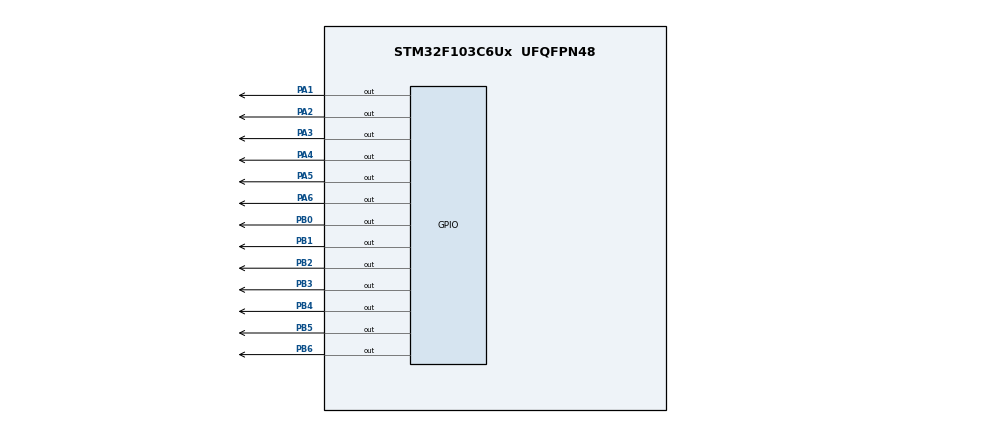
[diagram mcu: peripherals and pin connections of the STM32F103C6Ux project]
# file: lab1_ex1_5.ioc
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Mcu.Family=STM32F1
Mcu.Name=STM32F103C6Ux
Mcu.Package=UFQFPN48
NVIC.PriorityGroup=NVIC_PRIORITYGROUP_4
PA1.Signal=GPIO_Output
PA2.Signal=GPIO_Output
PA3.Signal=GPIO_Output
PA4.Signal=GPIO_Output
PA5.Signal=GPIO_Output
PA6.Signal=GPIO_Output
PB0.Signal=GPIO_Output
PB1.Signal=GPIO_Output
PB2.Signal=GPIO_Output
PB3.Signal=GPIO_Output
PB4.Signal=GPIO_Output
PB5.Signal=GPIO_Output
PB6.Signal=GPIO_Output
ProjectManager.HeapSize=0x200
ProjectManager.StackSize=0x400
ProjectManager.TargetToolchain=STM32CubeIDE
RCC.APB1Freq_Value=8000000
RCC.APB2Freq_Value=8000000
VP_SYS_VS_ND.Mode=No_Debug
board=custom

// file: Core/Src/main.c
/* USER CODE BEGIN Header */
/**
  ******************************************************************************
  * @file           : main.c
  * @brief          : Main program body
  ******************************************************************************
  * @attention
  *
  * <h2><center>&copy; Copyright (c) 2022 STMicroelectronics.
  * All rights reserved.</center></h2>
  *
  * This software component is licensed by ST under BSD 3-Clause license,
  * the "License"; You may not use this file except in compliance with the
  * License. You may obtain a copy of the License at:
  *                        opensource.org/licenses/BSD-3-Clause
  *
  ******************************************************************************
  */
/* USER CODE END Header */
#include "main.h"

void SystemClock_Config(void);
static void MX_GPIO_Init(void);

int main(void)
{

  /* MCU Configuration--------------------------------------------------------*/

  /* Reset of all peripherals, Initializes the Flash interface and the Systick. */
  HAL_Init();

  /* Configure the system clock */
  SystemClock_Config();

  /* Initialize all configured peripherals */
  MX_GPIO_Init();
  /* USER CODE BEGIN 2 */
  void display7SEG (int num){
  	char led7seg[10] = {0xC0, 0xF9, 0xA4, 0xB0, 0x99, 0x92, 0x82, 0xF8, 0x80, 0x90};
  	for (int i = 0; i < 7; i++){
  		HAL_GPIO_WritePin(GPIOB, GPIO_PIN_0 << i, (led7seg[num] >> i) & 1);
  	}
  }
  /* USER CODE END 2 */

  /* Infinite loop */
  /* USER CODE BEGIN WHILE */
  int counter = 9;
    while (1)
    {
  	  switch (counter){
  	  case 9: //1RED -2 GREEN
  		  HAL_GPIO_WritePin(GPIOA, GPIO_PIN_1, GPIO_PIN_RESET);
  		  HAL_GPIO_WritePin(GPIOA, GPIO_PIN_2, GPIO_PIN_SET);
  		  HAL_GPIO_WritePin(GPIOA, GPIO_PIN_3, GPIO_PIN_SET);
  		  HAL_GPIO_WritePin(GPIOA, GPIO_PIN_4, GPIO_PIN_SET);
  		  HAL_GPIO_WritePin(GPIOA, GPIO_PIN_5, GPIO_PIN_SET);
  		  HAL_GPIO_WritePin(GPIOA, GPIO_PIN_6, GPIO_PIN_RESET);
  		  display7SEG(4);
  		  counter --;
  		  break ;
  	  case 8:
  		  display7SEG(3);
  		  counter--;
  		  break;
  	  case 7:
  		  display7SEG(2);
  		  counter--;
  		  break ;
  	  case 6: //2YEL
  		  HAL_GPIO_WritePin(GPIOA, GPIO_PIN_5, GPIO_PIN_RESET );
  		  HAL_GPIO_WritePin(GPIOA, GPIO_PIN_6, GPIO_PIN_SET );
  		  display7SEG(1);
  		  counter--;
  		  break;
  	  case 5:
  		  display7SEG(0);
  		  counter--;
  		  break ;
  	  case 4: //1GREEN -2 RED
  		  HAL_GPIO_WritePin(GPIOA, GPIO_PIN_1, GPIO_PIN_SET );
  		  HAL_GPIO_WritePin(GPIOA, GPIO_PIN_3, GPIO_PIN_RESET );
  		  HAL_GPIO_WritePin(GPIOA, GPIO_PIN_4, GPIO_PIN_RESET );
  		  HAL_GPIO_WritePin(GPIOA, GPIO_PIN_5, GPIO_PIN_SET );
  		  display7SEG(2);
  		  counter--;
  		  break;
  	  case 3:
  		  display7SEG(1);
  		  counter--;
  		  break;
  	  case 2:
  		  display7SEG(0);
  		  counter--;
  		  break;
  	  case 1: //1YEL
  		  HAL_GPIO_WritePin(GPIOA, GPIO_PIN_2, GPIO_PIN_RESET );
  		  HAL_GPIO_WritePin(GPIOA, GPIO_PIN_3, GPIO_PIN_SET );
  		  display7SEG(1);
  		  counter--;
  		  break;
  	  case 0:
  		  display7SEG(0);
  		  counter += 9;
  		  break;
  	  }
  	  HAL_Delay(1000);
    }
}

void SystemClock_Config(void)
{
  RCC_OscInitTypeDef RCC_OscInitStruct = {0};
  RCC_ClkInitTypeDef RCC_ClkInitStruct = {0};

  /** Initializes the RCC Oscillators according to the specified parameters
  * in the RCC_OscInitTypeDef structure.
  */
  RCC_OscInitStruct.OscillatorType = RCC_OSCILLATORTYPE_HSI;
  RCC_OscInitStruct.HSIState = RCC_HSI_ON;
  RCC_OscInitStruct.HSICalibrationValue = RCC_HSICALIBRATION_DEFAULT;
  RCC_OscInitStruct.PLL.PLLState = RCC_PLL_NONE;
  if (HAL_RCC_OscConfig(&RCC_OscInitStruct) != HAL_OK)
  {
    Error_Handler();
  }
  /** Initializes the CPU, AHB and APB buses clocks
  */
  RCC_ClkInitStruct.ClockType = RCC_CLOCKTYPE_HCLK|RCC_CLOCKTYPE_SYSCLK
                              |RCC_CLOCKTYPE_PCLK1|RCC_CLOCKTYPE_PCLK2;
  RCC_ClkInitStruct.SYSCLKSource = RCC_SYSCLKSOURCE_HSI;
  RCC_ClkInitStruct.AHBCLKDivider = RCC_SYSCLK_DIV1;
  RCC_ClkInitStruct.APB1CLKDivider = RCC_HCLK_DIV1;
  RCC_ClkInitStruct.APB2CLKDivider = RCC_HCLK_DIV1;

  if (HAL_RCC_ClockConfig(&RCC_ClkInitStruct, FLASH_LATENCY_0) != HAL_OK)
  {
    Error_Handler();
  }
}

static void MX_GPIO_Init(void)
{
  GPIO_InitTypeDef GPIO_InitStruct = {0};

  /* GPIO Ports Clock Enable */
  __HAL_RCC_GPIOA_CLK_ENABLE();
  __HAL_RCC_GPIOB_CLK_ENABLE();

  /*Configure GPIO pin Output Level */
  HAL_GPIO_WritePin(GPIOA, GPIO_PIN_1|GPIO_PIN_2|GPIO_PIN_3|GPIO_PIN_4
                          |GPIO_PIN_5|GPIO_PIN_6, GPIO_PIN_RESET);

  /*Configure GPIO pin Output Level */
  HAL_GPIO_WritePin(GPIOB, GPIO_PIN_0|GPIO_PIN_1|GPIO_PIN_2|GPIO_PIN_3
                          |GPIO_PIN_4|GPIO_PIN_5|GPIO_PIN_6, GPIO_PIN_RESET);

  /*Configure GPIO pins : PA1 PA2 PA3 PA4
                           PA5 PA6 */
  GPIO_InitStruct.Pin = GPIO_PIN_1|GPIO_PIN_2|GPIO_PIN_3|GPIO_PIN_4
                          |GPIO_PIN_5|GPIO_PIN_6;
  GPIO_InitStruct.Mode = GPIO_MODE_OUTPUT_PP;
  GPIO_InitStruct.Pull = GPIO_NOPULL;
  GPIO_InitStruct.Speed = GPIO_SPEED_FREQ_LOW;
  HAL_GPIO_Init(GPIOA, &GPIO_InitStruct);

  /*Configure GPIO pins : PB0 PB1 PB2 PB3
                           PB4 PB5 PB6 */
  GPIO_InitStruct.Pin = GPIO_PIN_0|GPIO_PIN_1|GPIO_PIN_2|GPIO_PIN_3
                          |GPIO_PIN_4|GPIO_PIN_5|GPIO_PIN_6;
  GPIO_InitStruct.Mode = GPIO_MODE_OUTPUT_PP;
  GPIO_InitStruct.Pull = GPIO_NOPULL;
  GPIO_InitStruct.Speed = GPIO_SPEED_FREQ_LOW;
  HAL_GPIO_Init(GPIOB, &GPIO_InitStruct);

}

void Error_Handler(void)
{
  __disable_irq();
  while (1)
  {
  }
}

/************************ (C) COPYRIGHT STMicroelectronics *****END OF FILE****/
